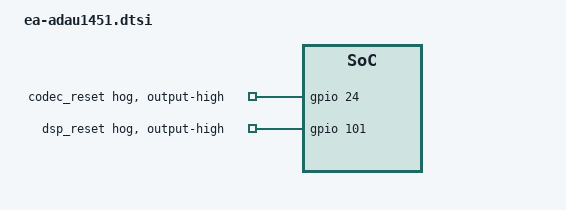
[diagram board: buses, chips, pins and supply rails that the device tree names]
// SPDX-License-Identifier: GPL-2.0
/* ADAU1451 DSP and codec resets, released for the boards that have them. */
#define EA_LINE_24	"codec_reset"
#define EA_LINE_101	"dsp_reset"

&gpio {
	codec-reset-hog {
		gpio-hog;
		gpios = <24 GPIO_ACTIVE_HIGH>;
		output-high;
		line-name = "codec_reset";
	};
	dsp-reset-hog {
		gpio-hog;
		gpios = <101 GPIO_ACTIVE_HIGH>;
		output-high;
		line-name = "dsp_reset";
	};
};
